# GD32A72_A74x register map
File version: 1.0
CPU: CM7 r2p1, little endian, MPU, FPU, DSP, 4 interrupt priority bits
Registers are 32-bit, read-write, reset 0x0 unless marked. A register's access mark holds for its fields unless they carry their own. Offsets are from the block's base; [hi:lo] are bit positions; {n}, {i} and the like mark numbered series.

## RCTL — Reset control unit
Base 0x49003C00
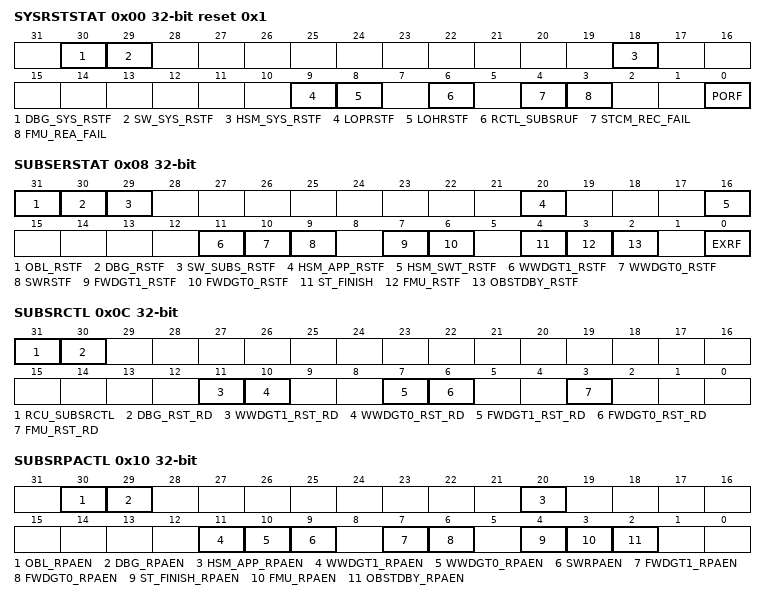
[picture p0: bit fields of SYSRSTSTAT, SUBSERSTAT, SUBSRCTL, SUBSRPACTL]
0x00 SYSRSTSTAT reset 0x1 — System Reset Status register
  [30] DBG_SYS_RSTF — System reset flag DBG_SYS_RSTF
  [29] SW_SYS_RSTF — System reset flag SW_SYS_RSTF
  [18] HSM_SYS_RSTF — System reset flag HSM_SYS_RSTF
  [9] LOPRSTF — Lost of PLL error reset flag
  [8] LOHRSTF — Lost of HXTAL error reset flag
  [6] RCTL_SUBSRUF — System reset flag RCTL_SUBSRUF
  [4] STCM_REC_FAIL — System reset flag STCM_REC_FAIL
  [3] FMU_REA_FAIL — System reset flag FMU_REA_FAIL
  [0] PORF — Power-on reset flag
0x04 BUSCTL — Bus control register
  [0] BUSCTL — Bus control bit
0x08 SUBSERSTAT — Subsystem/external reset status register
  [31] OBL_RSTF — Option byte loader reset flag
  [30] DBG_RSTF — Debug reset flag DBG_RSTF
  [29] SW_SUBS_RSTF — Subsystem reset flag SW_SUBS_RSTF
  [20] HSM_APP_RSTF — Subsystem reset flag HSM_APP_RSTF
  [16] HSM_SWT_RSTF — Subsystem reset flag HSM_WDGT_RSTF
  [11] WWDGT1_RSTF — Subsystem reset flag WWDGT1_RSTF
  [10] WWDGT0_RSTF — Subsystem reset flag WWDGT0_RSTF
  [9] SWRSTF — Software reset flag
  [7] FWDGT1_RSTF — Subsystem reset flag FWDGT1_RSTF
  [6] FWDGT0_RSTF — Subsystem reset flag FWDGT0_RSTF
  [4] ST_FINISH — Subsystem reset flag ST_FINISH
  [3] FMU_RSTF — Subsystem reset flag FMU_RSTF
  [2] OBSTDBY_RSTF — Subsystem reset flag OBSTDBY_RSTF
  [0] EXRF — External reset flag EXRF
0x0C SUBSRCTL — Subsystem reset control register
  [31] RCU_SUBSRCTL — OBL_RST disable control
  [30] DBG_RST_RD — DBG_RST_RD disable control
  [11] WWDGT1_RST_RD — WWDGT1_RST_RD disable control
  [10] WWDGT0_RST_RD — WWDGT0_RST_RD disable control
  [7] FWDGT1_RST_RD — FWDGT1_RST_RD disable control
  [6] FWDGT0_RST_RD — FWDGT0_RST_RD disable control
  [3] FMU_RST_RD — FMU_RD Disable Control
0x10 SUBSRPACTL access per field — Subsystem reset pin assert control register
  [30] OBL_RPAEN ro — Reset pin assert enable for OBL_RST
  [29] DBG_RPAEN ro — Reset pin assert enable for DBG_RST
  [20] HSM_APP_RPAEN ro — Reset pin assert enable for subsystem reset HSM_APP_RST
  [11] WWDGT1_RPAEN ro — Reset pin assert enable for subsystem reset WWDGT1_RST
  [10] WWDGT0_RPAEN ro — Reset pin assert enable for subsystem reset WWDGT0_RST
  [9] SWRPAEN ro — Reset pin assert enable for software reset
  [7] FWDGT1_RPAEN ro — Reset pin assert enable for subsystem reset FWDGT1_RST
  [6] FWDGT0_RPAEN ro — Reset pin assert enable for subsystem reset FWDGT0_RST
  [4] ST_FINISH_RPAEN rw — Reset pin assert enable for subsystem reset ST_FINISH
  [3] FMU_RPAEN ro — Reset pin assert enable for subsystem reset FMU_RST
  [2] OBSTDBY_RPAEN ro — Reset pin assert enable for standby reset
0x14 SUBSRMUCNT — Subsystem reset mode upgrade counter register
  [3:0] SUBSRMUCNT — Subsystem reset mode upgrade counter
0x18 SUBSRMUTH reset 0xF — Subsystem reset mode upgrade threshold register
  [3:0] SUBSRMUTH — Subsystem reset mode upgrade threshold
0x1C SYSMRUTH — System reset mode upgrade threshold register
  [3:0] SYSMRUTH — System reset mode upgrade threshold
0x20 ERPACFG — External reset pin assert configuration register
  [0] ERPAETEN — External reset pin assert enable
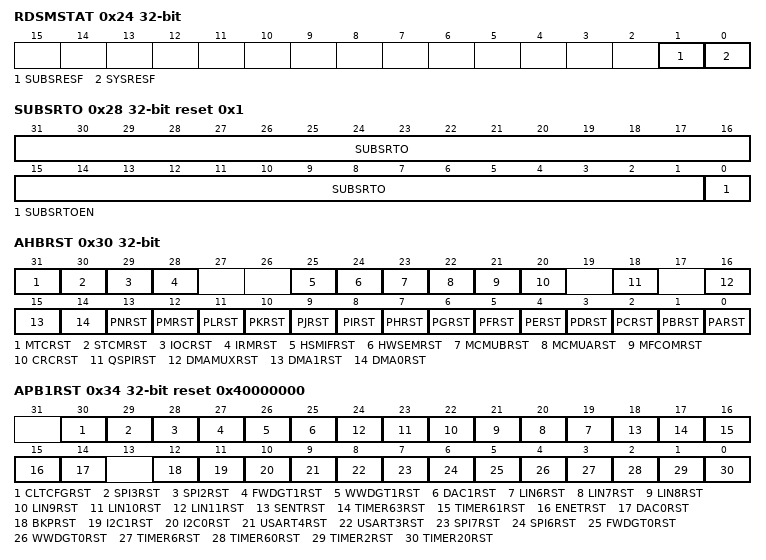
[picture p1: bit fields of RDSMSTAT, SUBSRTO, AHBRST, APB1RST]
0x24 RDSMSTAT — Reset during standby mode status register
  [1] SUBSRESF — Subsystem reset event occurred flag in standby mode
  [0] SYSRESF — System reset event occurred flag in standby mode
0x28 SUBSRTO reset 0x1 — Subsystem reset timeout register
  [31:1] SUBSRTO — Subsystem reset timer value
  [0] SUBSRTOEN — Subsystem reset timer enable
0x2C LPDBGSTAT ro — Low Power Debug Status Register
  [0] LPDBGF — Low-Power debug flag
0x30 AHBRST — AHB reset register
  [31] MTCRST — MTC reset enable
  [30] STCMRST — STCM reset enable
  [29] IOCRST — IOC reset enable
  [28] IRMRST — IRM reset enable
  [25] HSMIFRST — HSMIF reset enable
  [24] HWSEMRST — HWSEM reset enable
  [23] MCMUBRST — MCMUB reset enable
  [22] MCMUARST — MCMUA reset enable
  [21] MFCOMRST — MFCOM port A reset enable
  [20] CRCRST — CRC reset enable
  [18] QSPIRST — QSPI reset enable
  [16] DMAMUXRST — DMAMUX reset enable
  [15] DMA1RST — DMA1 reset enable
  [14] DMA0RST — DMA0 reset enable
  [13] PNRST — GPIO port N reset enable
  [12] PMRST — GPIO port M reset enable
  [11] PLRST — GPIO port L reset enable
  [10] PKRST — GPIO port K reset enable
  [9] PJRST — GPIO port J reset enable
  [8] PIRST — GPIO port I reset enable
  [7] PHRST — GPIO port H reset enable
  [6] PGRST — GPIO port G reset enable
  [5] PFRST — GPIO port F reset enable
  [4] PERST — GPIO port E reset enable
  [3] PDRST — GPIO port D reset enable
  [2] PCRST — GPIO port C reset enable
  [1] PBRST — GPIO port B reset enable
  [0] PARST — GPIO port A reset enable
0x34 APB1RST reset 0x40000000 — APB1 reset register
  [30] CLTCFGRST — CLTCFG reset enable
  [29] SPI3RST — SPI3 reset enable
  [28] SPI2RST — SPI2 reset enable
  [27] FWDGT1RST — Free watchdog timer reset enable
  [26] WWDGT1RST — Window watchdog timer reset enable
  [25] DAC1RST — DAC1 reset enable
  [n+13] LIN{n}RST (n=6..11) — LIN{n} reset enable
  [18] SENTRST — SENT timer reset enable
  [17] TIMER63RST — TIMER63 timer reset enable
  [16] TIMER61RST — TIMER61 timer reset enable
  [15] ENETRST — ENET reset enable
  [14] DAC0RST — DAC0 reset enable
  [12] BKPRST — BKP reset enable
  [11] I2C1RST — I2C1 reset enable
  [10] I2C0RST — I2C0 reset enable
  [9] USART4RST — USART4 reset enable
  [8] USART3RST — USART3 reset enable
  [7] SPI7RST — SPI7 reset enable
  [6] SPI6RST — SPI6 reset enable
  [5] FWDGT0RST — Free watchdog timer reset enable
  [4] WWDGT0RST — Window watchdog timer reset enable
  [3] TIMER6RST — TIMER6 timer reset enable
  [2] TIMER60RST — TIMER60 reset enable
  [1] TIMER2RST — TIMER2 reset enable
  [0] TIMER20RST — TIMER20 reset enable
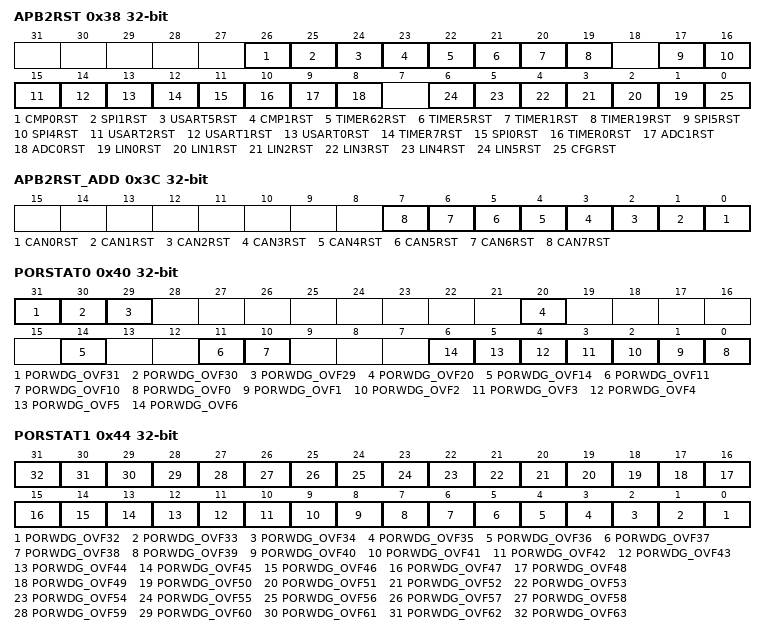
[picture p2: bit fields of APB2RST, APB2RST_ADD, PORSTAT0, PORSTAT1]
0x38 APB2RST — APB2 reset register
  [26] CMP0RST — Comparator0 reset enable
  [25] SPI1RST — SPI1 reset enable
  [24] USART5RST — USART5 reset enable
  [23] CMP1RST — Comparator1 reset enable
  [22] TIMER62RST — TIMER62 timer reset enable
  [21] TIMER5RST — TIMER5 timer reset enable
  [20] TIMER1RST — TIMER1 timer reset enable
  [19] TIMER19RST — TIMER19 timer reset enable
  [17] SPI5RST — SPI5 reset enable
  [16] SPI4RST — SPI4 reset enable
  [15] USART2RST — USART2 reset enable
  [14] USART1RST — USART1 reset enable
  [13] USART0RST — USART0 reset enable
  [12] TIMER7RST — TIMER7 timer reset enable
  [11] SPI0RST — SPI0 reset enable
  [10] TIMER0RST — TIMER0 timer reset enable
  [9] ADC1RST — ADC1 interface reset enable
  [8] ADC0RST — ADC interface reset enable
  [n+1] LIN{n}RST (n=0..5) — LIN{n} reset enable
  [0] CFGRST — System configuration reset enable
0x3C APB2RST_ADD — APB2 reset additional register
  [n] CAN{n}RST (n=0..7) — CAN{n} reset enable
0x40 PORSTAT0 access per field — Power-on reset during POR watchdog overflows status register 0
  [31] PORWDG_OVF31 rw — PORWDG_OVF31 captures RCTL reset event (if occurred) while the device is in standby mode
  [30] PORWDG_OVF30 ro — PORWDG_OVF30 captures the status of standby exit acknowledgement by PMU when POR_WDG overflows
  [29] PORWDG_OVF29 rw — PORWDG_OVF29 captures the status of standby entry request initiated by PMU when PORWDG overflows
  [20] PORWDG_OVF20 rw — PORWDG_STAT20 captures the status of subsystem reset sequence process SYSRST0 when PORWDG overflows
  [14] PORWDG_OVF14 rw — PORWDG_OVF14 captures the status of subsystem reset sequence process SUBSRST9 when PORWDG overflows
  [11] PORWDG_OVF11 rw — PORWDG_OVF11 captures the status of subsystem reset sequence process SUBSRST8 when PORWDG overflows
  [10] PORWDG_OVF10 rw — PORWDG_OVF10 captures the status of subsystem reset sequence process SUBSRST7 when PORWDG overflows
  [n] PORWDG_OVF{n} rw (n=0..6) — PORWDG_OVF{n} captures the status of subsystem reset sequence process SUBSRST{n} when PORWDG overflows
0x44 PORSTAT1 — Power-on reset during POR watchdog overflows status register 1
  [n-32] PORWDG_OVF{n} (n=32..63) — This bit captures RCTL subsystem/external event status register when PORWDG overflows
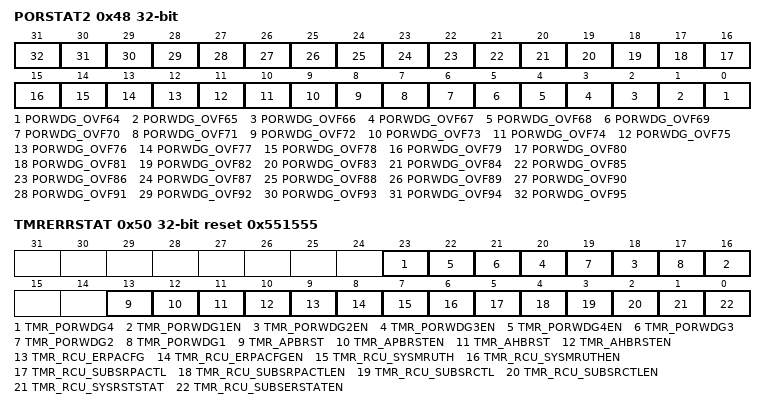
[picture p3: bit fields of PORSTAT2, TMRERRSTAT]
0x48 PORSTAT2 — Power-on reset during POR watchdog overflows status register 2
  [n-64] PORWDG_OVF{n} (n=64..95) — This bit captures RCTL system event status register when PORWDG overflows
0x4C PORSTAT3 — Power-on reset during POR watchdog overflows status register 3
  [0] PORWDG_OVF96 — This bit captures PORWDG reset event if PORWDG initiates a POR sequence
0x50 TMRERRSTAT reset 0x551555 — Triple modular redundancy error status register
  [23] TMR_PORWDG4 — TMR_PORWDG4 TMR error status
  [2n+14] TMR_PORWDG{n}EN (n=1..4) — TMR_PORWDG{n} TMR error output enable
  [21] TMR_PORWDG3 — TMR_PORWDG3 TMR error status
  [19] TMR_PORWDG2 — TMR_PORWDG32 TMR error status
  [17] TMR_PORWDG1 — TMR_PORWDG1 TMR error status
  [13] TMR_APBRST — APBRST1/2 TMR error status
  [12] TMR_APBRSTEN — APBRST1/2 TMR error output enable
  [11] TMR_AHBRST — AHBRST TMR error status
  [10] TMR_AHBRSTEN — AHBRST TMR error output enable
  [9] TMR_RCU_ERPACFG — RCU_ERPACFG TMR error status
  [8] TMR_RCU_ERPACFGEN — RCU_ERPACFG TMR error output enable
  [7] TMR_RCU_SYSMRUTH — RCU_SYSMRUTH TMR error status
  [6] TMR_RCU_SYSMRUTHEN — RCU_SYSMRUTH TMR error output enable
  [5] TMR_RCU_SUBSRPACTL — RCU_SUBSRPACTL TMR error status
  [4] TMR_RCU_SUBSRPACTLEN — RCU_SUBSRPACTL TMR error output enable
  [3] TMR_RCU_SUBSRCTL — RCU_SUBSRCTL TMR error status
  [2] TMR_RCU_SUBSRCTLEN — RCU_SUBSRCTL TMR error output enable
  [1] TMR_RCU_SYSRSTSTAT — RCU_SYSRSTSTAT TMR error status
  [0] TMR_RCU_SUBSERSTATEN — RCU_SUBSERSTAT TMR error output enable
0x54 SYSRSTUCNT — System reset upgrade counter register
  [3:0] SUBSRTOEN — System reset upgrade counter
